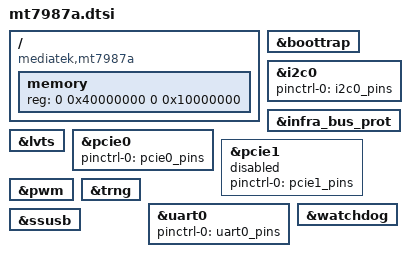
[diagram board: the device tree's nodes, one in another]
// SPDX-License-Identifier: (GPL-2.0 OR MIT)
/*
 * Copyright (C) 2023 MediaTek Inc.
 * Author: Sam.Shih <sam.shih@mediatek.com>
 */

/dts-v1/;
#include <dt-bindings/leds/common.h>
#include "mt7987.dtsi"

/ {
	compatible = "mediatek,mt7987a", "mediatek,mt7987";

	memory {
		reg = <0 0x40000000 0 0x10000000>;
	};

};

&boottrap {
	status = "okay";
};

&i2c0 {
	pinctrl-names = "default";
	pinctrl-0 = <&i2c0_pins>;
	status = "okay";
};

&infra_bus_prot {
	status = "okay";
};

&lvts {
	status = "okay";
};

&pcie0 {
	pinctrl-names = "default";
	pinctrl-0 = <&pcie0_pins>;
	status = "okay";
};

&pcie1 {
	pinctrl-names = "default";
	pinctrl-0 = <&pcie1_pins>;
	status = "disabled";
};

&pwm {
	status = "okay";
};

&trng {
	status = "okay";
};

&uart0 {
	pinctrl-names = "default";
	pinctrl-0 = <&uart0_pins>;
	status = "okay";
};

&watchdog {
	status = "okay";
};

&ssusb {
	status = "okay";
};
